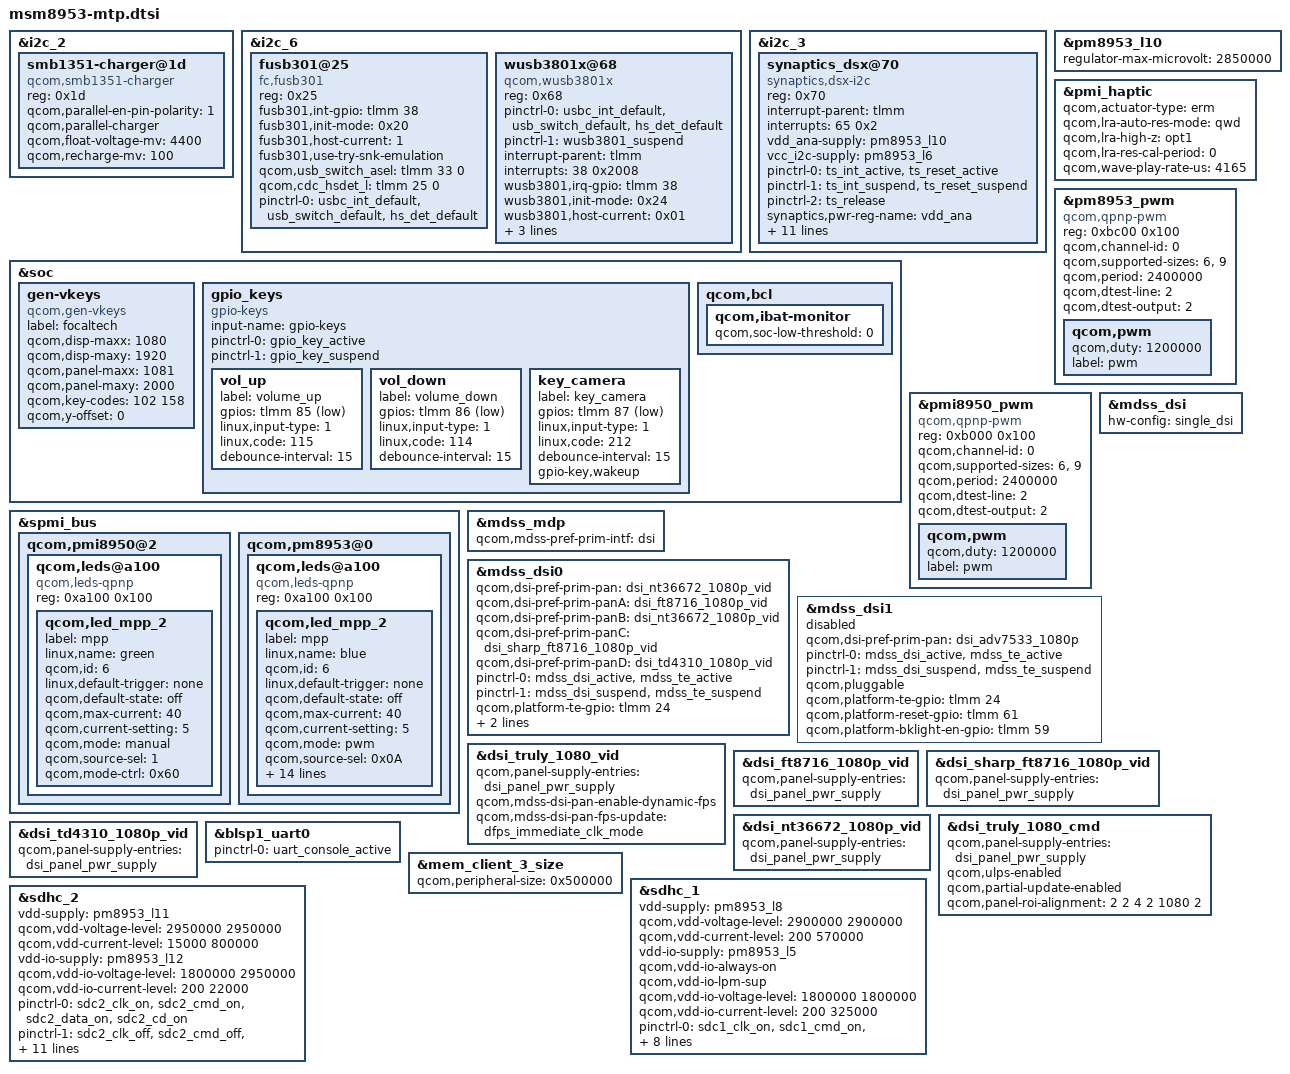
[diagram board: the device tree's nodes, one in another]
/*
 * Copyright (c) 2015-2017, The Linux Foundation. All rights reserved.
 *
 * This program is free software; you can redistribute it and/or modify
 * it under the terms of the GNU General Public License version 2 and
 * only version 2 as published by the Free Software Foundation.
 *
 * This program is distributed in the hope that it will be useful,
 * but WITHOUT ANY WARRANTY; without even the implied warranty of
 * MERCHANTABILITY or FITNESS FOR A PARTICULAR PURPOSE.  See the
 * GNU General Public License for more details.
 */

#include "msm8953-pinctrl.dtsi"
#include "msm8953-audio-mtp.dtsi"

//ONTIM:houzn add new devices

&i2c_2 {
	/* Parallel-charger configuration */
	smb1351-charger@1d {
		compatible = "qcom,smb1351-charger";
		reg = <0x1d>;
		qcom,parallel-en-pin-polarity = <1>;
		qcom,parallel-charger;
		qcom,float-voltage-mv = <4400>;
		qcom,recharge-mv = <100>;
	};
};


&i2c_6 {
	fusb301@25 {
		compatible = "fc,fusb301";
		reg = <0x25>;
		fusb301,int-gpio = <&tlmm 38 0>;
		fusb301,init-mode = /bits/ 8 <0x20>;
		fusb301,host-current = /bits/ 8 <1>;
		fusb301,use-try-snk-emulation;
		qcom,usb_switch_asel = <&tlmm 33 0>;
		qcom,cdc_hsdet_l = <&tlmm 25 0>;
		pinctrl-names = "default";
		pinctrl-0 = <&usbc_int_default &usb_switch_default &hs_det_default>;
	};

	wusb3801x@68 {
		compatible = "qcom,wusb3801x";
		reg = <0x68>;
		pinctrl-names = "pmx_wusb3801_active",
                        "pmx_wusb3801_suspend";
		pinctrl-0 = <&usbc_int_default &usb_switch_default &hs_det_default>;
		pinctrl-1 = <&wusb3801_suspend>;
		interrupt-parent = <&tlmm>;
		interrupts = <38 0x2008>;
		interrupt-names = "wusb3801_int_irq";
		wusb3801,irq-gpio = <&tlmm 38 0x2008>;
		wusb3801,init-mode = <0x24>;
		wusb3801,host-current = <0x01>;
		wusb3801,drp-toggle-time = <40>;
		qcom,usb_switch_asel = <&tlmm 33 0>;
		qcom,cdc_hsdet_l = <&tlmm 25 0>;
	};
};

//add end

&i2c_3 { /* BLSP2 QUP1  */
	status = "okay";

	synaptics_dsx@70 {
		compatible = "synaptics,dsx-i2c";
		reg = <0x70>;
		interrupt-parent = <&tlmm>;
		interrupts = <65 0x2>;
		vdd_ana-supply = <&pm8953_l10>;
		vcc_i2c-supply = <&pm8953_l6>;
		pinctrl-names = "pmx_ts_active","pmx_ts_suspend","pmx_ts_release";
		pinctrl-0 = <&ts_int_active &ts_reset_active>;
		pinctrl-1 = <&ts_int_suspend &ts_reset_suspend>;
		pinctrl-2 = <&ts_release>;
		synaptics,pwr-reg-name = "vdd_ana";
		synaptics,bus-reg-name = "vcc_i2c";
		synaptics,ub-i2c-addr = <0x2c>;
		synaptics,irq-gpio =  <&tlmm 65 0x2008>;
		synaptics,reset-gpio = <&tlmm 64 0x0>;
		synaptics,irq-on-state = <0>;
		synaptics,power-delay-ms = <200>;
		synaptics,reset-delay-ms = <200>;
		synaptics,reset-on-state = <0>;
		synaptics,reset-active-ms = <20>;
		synaptics,y-flip = <1>;
		synaptics,x-flip = <1>;
		/* uncomment and update line below as appropriate if there are 0D buttons */
		/* synaptics,cap-button-codes = <102 158>; */
		/* uncomment and update lines below as appropriate if there are virtual buttons */
		/* synaptics,vir-button-codes = <102 100 900 100 60 158 300 900 100 60>; */
		/* synaptics,max-y-for-2d = <800>; */
	};
};


&pm8953_l10 {
	regulator-max-microvolt = <2850000>;
};

&soc {
	gen-vkeys {
	        compatible = "qcom,gen-vkeys";
	        label = "focaltech";
	        qcom,disp-maxx = <1080>;
	        qcom,disp-maxy = <1920>;
	        qcom,panel-maxx = <1081>;
	        qcom,panel-maxy = <2000>;
	        qcom,key-codes = <102 158 >;
	        qcom,y-offset = <0>;
	};
	gpio_keys {
		compatible = "gpio-keys";
		input-name = "gpio-keys";
		pinctrl-names = "tlmm_gpio_key_active","tlmm_gpio_key_suspend";
		pinctrl-0 = <&gpio_key_active>;
		pinctrl-1 = <&gpio_key_suspend>;

		vol_up {
			label = "volume_up";
			gpios = <&tlmm 85 0x1>;
			linux,input-type = <1>;
			linux,code = <115>;
			debounce-interval = <15>;
		};

		vol_down {
			label = "volume_down";
			gpios = <&tlmm 86 0x1>;
			linux,input-type = <1>;
			linux,code = <114>;
			debounce-interval = <15>;
		};
		key_camera {
			label = "key_camera";
			gpios = <&tlmm 87 0x1>;
			linux,input-type = <1>;
			linux,code = <212>;
			debounce-interval = <15>;
			gpio-key,wakeup;
		};
	};

};

&pmi_haptic{
	qcom,actuator-type = "erm";
	qcom,lra-auto-res-mode="qwd";
	qcom,lra-high-z="opt1";
	qcom,lra-res-cal-period = <0>;
	qcom,wave-play-rate-us = <4165>;
};

&spmi_bus {
	qcom,pmi8950@2 {
		qcom,leds@a100 {
			compatible = "qcom,leds-qpnp";
			reg = <0xa100 0x100>;
			status = "okay";
			qcom,led_mpp_2 {
				label = "mpp";
				linux,name = "green";
				qcom,id = <6>;
				linux,default-trigger = "none";
				qcom,default-state = "off";
				qcom,max-current = <40>;
				qcom,current-setting = <5>;
				qcom,mode = "manual";
				qcom,source-sel = <1>;
				qcom,mode-ctrl = <0x60>;
			};
		};
	};
};
#if 0

&spmi_bus {
	qcom,pm8953@0 {
		qcom,leds@a100 {
			compatible = "qcom,leds-qpnp";
			reg = <0xa100 0x100>;
			status = "okay";
			qcom,led_mpp_2 {
				label = "mpp";
				linux,name = "blue";
				qcom,id = <6>;
				linux,default-trigger = "none";
				qcom,default-state = "off";
				qcom,max-current = <40>;
				qcom,current-setting = <5>;
				qcom,mode = "pwm";
				qcom,source-sel = <0x0A>;
				qcom,mode-ctrl = <0x10>;
				pwms = <&pm8953_pwm 0 0>;
				qcom,pwm-us = <2400000>;
				qcom,pwm-channel = <0>;
				pwm-names = "blue";
			};
		};
	};
};


&pm8953_pwm {
	status = "okay";
	compatible = "qcom,qpnp-pwm";
	reg = <0xbc00 0x100>;
	reg-names = "qpnp-lpg-channel-base";
	qcom,channel-id = <0>;
	qcom,supported-sizes = <6>, <9>;
	qcom,period = <2400000>;
	#pwm-cells = <2>;
	qcom,dtest-line = <2>;
	qcom,dtest-output = <2>;
	qcom,pwm {
		qcom,duty = <1200000>;
		label = "pwm";
	};
};
#else

&spmi_bus {
	qcom,pm8953@0 {
		qcom,leds@a100 {
			compatible = "qcom,leds-qpnp";
			reg = <0xa100 0x100>;
			status = "okay";
			qcom,led_mpp_2 {
				label = "mpp";
				linux,name = "blue";
				qcom,id = <6>;
				linux,default-trigger = "none";
				qcom,default-state = "off";
				qcom,max-current = <40>;
				qcom,current-setting = <5>;
				qcom,mode = "pwm";
				qcom,source-sel = <0x0A>;
				qcom,mode-ctrl = <0x60>;
				pwms = <&pm8953_pwm 0 0>;
				qcom,pwm-us = <1000>;
				qcom,pwm-channel = <0>;
				pwm-names = "blue";

                qcom,start-idx = <1>;
                qcom,idx-len = <10>;
                qcom,duty-pcts = [00 19 32 4B 64
                            64 4B 32 19 00];
                qcom,lut-flags = <3>;
                qcom,pause-lo = <0>;
                qcom,pause-hi = <0>;
                qcom,ramp-step-ms = <255>;
                qcom,use-blink;
			};
		};
	};
};

&pm8953_pwm {
	status = "okay";
	compatible = "qcom,qpnp-pwm";
	reg = <0xbc00 0x100>;
	reg-names = "qpnp-lpg-channel-base";
	qcom,channel-id = <0>;
	qcom,supported-sizes = <6>, <9>;
	qcom,period = <2400000>;
	#pwm-cells = <2>;
	qcom,dtest-line = <2>;
	qcom,dtest-output = <2>;
	qcom,pwm {
		qcom,duty = <1200000>;
		label = "pwm";
	};
};

&pmi8950_pwm {
	status = "okay";
	compatible = "qcom,qpnp-pwm";
	reg = <0xb000 0x100>;
	reg-names = "qpnp-lpg-channel-base";
	qcom,channel-id = <0>;
	qcom,supported-sizes = <6>, <9>;
	qcom,period = <2400000>;
	#pwm-cells = <2>;
	qcom,dtest-line = <2>;
	qcom,dtest-output = <2>;
	qcom,pwm {
		qcom,duty = <1200000>;
		label = "pwm";
	};
};

#endif

#include "msm8953-mdss-panels.dtsi"

&mdss_mdp {
	qcom,mdss-pref-prim-intf = "dsi";
};

&mdss_dsi {
	hw-config = "single_dsi";
};

&mdss_dsi0 {
	qcom,dsi-pref-prim-pan = <&dsi_nt36672_1080p_vid>;
	qcom,dsi-pref-prim-panA = <&dsi_ft8716_1080p_vid>;
	qcom,dsi-pref-prim-panB = <&dsi_nt36672_1080p_vid>;
	qcom,dsi-pref-prim-panC = <&dsi_sharp_ft8716_1080p_vid>;
	qcom,dsi-pref-prim-panD = <&dsi_td4310_1080p_vid>;
	pinctrl-names = "mdss_default", "mdss_sleep";
	pinctrl-0 = <&mdss_dsi_active &mdss_te_active>;
	pinctrl-1 = <&mdss_dsi_suspend &mdss_te_suspend>;

	qcom,platform-te-gpio = <&tlmm 24 0>;
	qcom,platform-reset-gpio = <&tlmm 61 0>;
	qcom,platform-bklight-en-gpio = <&tlmm 59 0>;
};

&mdss_dsi1 {
	status = "disabled";
	qcom,dsi-pref-prim-pan = <&dsi_adv7533_1080p>;
	pinctrl-names = "mdss_default", "mdss_sleep";
	pinctrl-0 = <&mdss_dsi_active &mdss_te_active>;
	pinctrl-1 = <&mdss_dsi_suspend &mdss_te_suspend>;

	qcom,pluggable;
	qcom,platform-te-gpio = <&tlmm 24 0>;
	qcom,platform-reset-gpio = <&tlmm 61 0>;
	qcom,platform-bklight-en-gpio = <&tlmm 59 0>;
};

&dsi_truly_1080_vid {
	qcom,panel-supply-entries = <&dsi_panel_pwr_supply>;
	qcom,mdss-dsi-pan-enable-dynamic-fps;
	qcom,mdss-dsi-pan-fps-update = "dfps_immediate_clk_mode";
};

&dsi_ft8716_1080p_vid {
	qcom,panel-supply-entries = <&dsi_panel_pwr_supply>;
	//qcom,mdss-dsi-pan-enable-dynamic-fps;   //wanggang  panel NG mask line
	//qcom,mdss-dsi-pan-fps-update = "dfps_immediate_clk_mode";
};


&dsi_sharp_ft8716_1080p_vid {
	qcom,panel-supply-entries = <&dsi_panel_pwr_supply>;
	//qcom,mdss-dsi-pan-enable-dynamic-fps;
	//qcom,mdss-dsi-pan-fps-update = "dfps_immediate_clk_mode";
};

&dsi_nt36672_1080p_vid {
	qcom,panel-supply-entries = <&dsi_panel_pwr_supply>;
	//qcom,mdss-dsi-pan-enable-dynamic-fps;
	//qcom,mdss-dsi-pan-fps-update = "dfps_immediate_clk_mode";
};

&dsi_truly_1080_cmd {
	qcom,panel-supply-entries = <&dsi_panel_pwr_supply>;
	qcom,ulps-enabled;
	qcom,partial-update-enabled;
	qcom,panel-roi-alignment = <2 2 4 2 1080 2>;
};

&dsi_td4310_1080p_vid {
	qcom,panel-supply-entries = <&dsi_panel_pwr_supply>;
	//qcom,mdss-dsi-pan-enable-dynamic-fps;
	//qcom,mdss-dsi-pan-fps-update = "dfps_immediate_clk_mode";
};

&blsp1_uart0 {
	status = "ok";
	pinctrl-names = "default";
	pinctrl-0 = <&uart_console_active>;
};

&mem_client_3_size {
	qcom,peripheral-size = <0x500000>;
};

&sdhc_1 {
	/* device core power supply */
	vdd-supply = <&pm8953_l8>;
	qcom,vdd-voltage-level = <2900000 2900000>;
	qcom,vdd-current-level = <200 570000>;

	/* device communication power supply */
	vdd-io-supply = <&pm8953_l5>;
	qcom,vdd-io-always-on;
	qcom,vdd-io-lpm-sup;
	qcom,vdd-io-voltage-level = <1800000 1800000>;
	qcom,vdd-io-current-level = <200 325000>;

	pinctrl-names = "active", "sleep";
	pinctrl-0 = <&sdc1_clk_on &sdc1_cmd_on &sdc1_data_on  &sdc1_rclk_on>;
	pinctrl-1 = <&sdc1_clk_off &sdc1_cmd_off &sdc1_data_off &sdc1_rclk_off>;

	qcom,clk-rates = <400000 20000000 25000000 50000000 100000000 192000000
								384000000>;
	qcom,nonremovable;
	qcom,bus-speed-mode = "HS400_1p8v", "HS200_1p8v", "DDR_1p8v";

	status = "ok";
};

&sdhc_2 {
	/* device core power supply */
	vdd-supply = <&pm8953_l11>;
	qcom,vdd-voltage-level = <2950000 2950000>;
	qcom,vdd-current-level = <15000 800000>;

	/* device communication power supply */
	vdd-io-supply = <&pm8953_l12>;
	qcom,vdd-io-voltage-level = <1800000 2950000>;
	qcom,vdd-io-current-level = <200 22000>;

	pinctrl-names = "active", "sleep";
	pinctrl-0 = <&sdc2_clk_on &sdc2_cmd_on &sdc2_data_on &sdc2_cd_on>;
	pinctrl-1 = <&sdc2_clk_off &sdc2_cmd_off &sdc2_data_off>;

	#address-cells = <0>;
	interrupt-parent = <&sdhc_2>;
	interrupts = <0 1 2>;
	#interrupt-cells = <1>;
	interrupt-map-mask = <0xffffffff>;
	interrupt-map = <0 &intc 0 125 0
		1 &intc 0 221 0
		2 &tlmm 133 0>;
	interrupt-names = "hc_irq", "pwr_irq", "status_irq";
	cd-gpios = <&tlmm 133 0x0>;

	qcom,clk-rates = <400000 20000000 25000000 50000000 100000000
								200000000>;
	qcom,bus-speed-mode = "SDR12", "SDR25", "SDR50", "DDR50", "SDR104";

	status = "ok";
};
// ontim:houzn disable typec on pmic as hw
/*
&pm8953_typec {
	ss-mux-supply = <&pm8953_l13>;
	qcom,ssmux-gpio = <&tlmm 139 GPIO_ACTIVE_HIGH>;
	pinctrl-names = "default";
	pinctrl-0 = <&typec_ssmux_config>;
};
*/

&soc {
    qcom,bcl {
        qcom,ibat-monitor {
            qcom,soc-low-threshold = <0>;
        };
    };
};

